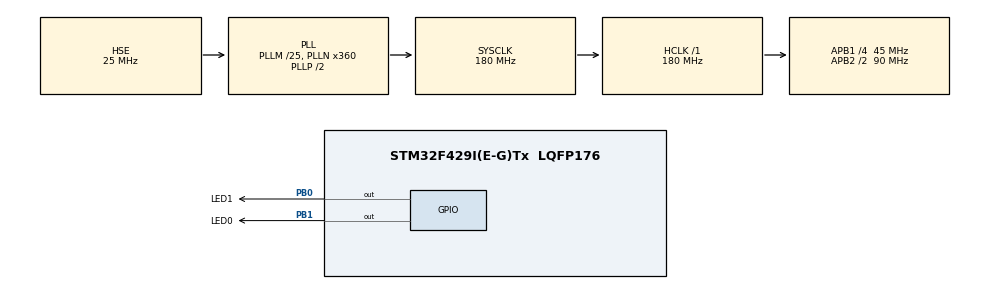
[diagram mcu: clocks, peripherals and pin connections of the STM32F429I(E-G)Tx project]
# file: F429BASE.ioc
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FREERTOS.Tasks01=defaultTask,24,128,StartDefaultTask,Default,NULL,Dynamic,NULL,NULL;myTask_LED0,8,128,StartTask_LED0,Default,NULL,Dynamic,NULL,NULL;myTask_LED1,8,128,StartTask_LED1,Default,NULL,Dynamic,NULL,NULL
Mcu.Family=STM32F4
Mcu.Name=STM32F429I(E-G)Tx
Mcu.Package=LQFP176
NVIC.PriorityGroup=NVIC_PRIORITYGROUP_4
NVIC.TIM6_DAC_IRQn=true\:15\:0\:false\:false\:true\:false\:false\:true\:true
NVIC.TimeBase=TIM6_DAC_IRQn
NVIC.TimeBaseIP=TIM6
PA13.Mode=Serial_Wire
PA13.Signal=SYS_JTMS-SWDIO
PA14.Mode=Serial_Wire
PA14.Signal=SYS_JTCK-SWCLK
PB0.GPIO_Label=LED1
PB0.Signal=GPIO_Output
PB1.GPIO_Label=LED0
PB1.Signal=GPIO_Output
PC14/OSC32_IN.Mode=LSE-External-Oscillator
PC14/OSC32_IN.Signal=RCC_OSC32_IN
PC15/OSC32_OUT.Mode=LSE-External-Oscillator
PC15/OSC32_OUT.Signal=RCC_OSC32_OUT
PH0/OSC_IN.Mode=HSE-External-Oscillator
PH0/OSC_IN.Signal=RCC_OSC_IN
PH1/OSC_OUT.Mode=HSE-External-Oscillator
PH1/OSC_OUT.Signal=RCC_OSC_OUT
ProjectManager.HeapSize=0x200
ProjectManager.StackSize=0x400
ProjectManager.TargetToolchain=CMake
RCC.48MHZClocksFreq_Value=90000000
RCC.AHBFreq_Value=180000000
RCC.APB1CLKDivider=RCC_HCLK_DIV4
RCC.APB1Freq_Value=45000000
RCC.APB1TimFreq_Value=90000000
RCC.APB2CLKDivider=RCC_HCLK_DIV2
RCC.APB2Freq_Value=90000000
RCC.APB2TimFreq_Value=180000000
RCC.CortexFreq_Value=180000000
RCC.HCLKFreq_Value=180000000
RCC.HSE_VALUE=25000000
RCC.HSI_VALUE=16000000
RCC.PLLM=25
RCC.PLLN=360
RCC.PLLSAIN=100
RCC.PLLSourceVirtual=RCC_PLLSOURCE_HSE
RCC.SYSCLKFreq_VALUE=180000000
RCC.SYSCLKSource=RCC_SYSCLKSOURCE_PLLCLK
RCC.VCOOutputFreq_Value=360000000
VP_FREERTOS_VS_CMSIS_V2.Mode=CMSIS_V2
VP_SYS_VS_tim6.Mode=TIM6
board=custom

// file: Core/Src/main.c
/* USER CODE BEGIN Header */
/**
  ******************************************************************************
  * @file           : main.c
  * @brief          : Main program body
  ******************************************************************************
  * @attention
  *
  * Copyright (c) 2026 STMicroelectronics.
  * All rights reserved.
  *
  * This software is licensed under terms that can be found in the LICENSE file
  * in the root directory of this software component.
  * If no LICENSE file comes with this software, it is provided AS-IS.
  *
  ******************************************************************************
  */
/* USER CODE END Header */
#include "main.h"
#include "cmsis_os.h"
#include "gpio.h"

void SystemClock_Config(void);
void MX_FREERTOS_Init(void);

int main(void)
{

  /* MCU Configuration--------------------------------------------------------*/

  /* Reset of all peripherals, Initializes the Flash interface and the Systick. */
  HAL_Init();

  /* Configure the system clock */
  SystemClock_Config();

  /* Initialize all configured peripherals */
  MX_GPIO_Init();

  /* Init scheduler */
  osKernelInitialize();  /* Call init function for freertos objects (in cmsis_os2.c) */
  MX_FREERTOS_Init();

  /* Start scheduler */
  osKernelStart();

  /* We should never get here as control is now taken by the scheduler */

  /* Infinite loop */
  while (1)
  {

    /* USER CODE BEGIN 3 */
      HAL_GPIO_TogglePin(LED0_GPIO_Port,LED0_Pin);
      //HAL_GPIO_TogglePin(LED1_GPIO_Port,LED1_Pin);
      HAL_Delay(500);
  }
  /* USER CODE END 3 */
}

void SystemClock_Config(void)
{
  RCC_OscInitTypeDef RCC_OscInitStruct = {0};
  RCC_ClkInitTypeDef RCC_ClkInitStruct = {0};

  /** Configure the main internal regulator output voltage
  */
  __HAL_RCC_PWR_CLK_ENABLE();
  __HAL_PWR_VOLTAGESCALING_CONFIG(PWR_REGULATOR_VOLTAGE_SCALE1);

  /** Initializes the RCC Oscillators according to the specified parameters
  * in the RCC_OscInitTypeDef structure.
  */
  RCC_OscInitStruct.OscillatorType = RCC_OSCILLATORTYPE_HSE;
  RCC_OscInitStruct.HSEState = RCC_HSE_ON;
  RCC_OscInitStruct.PLL.PLLState = RCC_PLL_ON;
  RCC_OscInitStruct.PLL.PLLSource = RCC_PLLSOURCE_HSE;
  RCC_OscInitStruct.PLL.PLLM = 25;
  RCC_OscInitStruct.PLL.PLLN = 360;
  RCC_OscInitStruct.PLL.PLLP = RCC_PLLP_DIV2;
  RCC_OscInitStruct.PLL.PLLQ = 4;
  if (HAL_RCC_OscConfig(&RCC_OscInitStruct) != HAL_OK)
  {
    Error_Handler();
  }

  /** Activate the Over-Drive mode
  */
  if (HAL_PWREx_EnableOverDrive() != HAL_OK)
  {
    Error_Handler();
  }

  /** Initializes the CPU, AHB and APB buses clocks
  */
  RCC_ClkInitStruct.ClockType = RCC_CLOCKTYPE_HCLK|RCC_CLOCKTYPE_SYSCLK
                              |RCC_CLOCKTYPE_PCLK1|RCC_CLOCKTYPE_PCLK2;
  RCC_ClkInitStruct.SYSCLKSource = RCC_SYSCLKSOURCE_PLLCLK;
  RCC_ClkInitStruct.AHBCLKDivider = RCC_SYSCLK_DIV1;
  RCC_ClkInitStruct.APB1CLKDivider = RCC_HCLK_DIV4;
  RCC_ClkInitStruct.APB2CLKDivider = RCC_HCLK_DIV2;

  if (HAL_RCC_ClockConfig(&RCC_ClkInitStruct, FLASH_LATENCY_5) != HAL_OK)
  {
    Error_Handler();
  }
}

void HAL_TIM_PeriodElapsedCallback(TIM_HandleTypeDef *htim)
{
  if (htim->Instance == TIM6)
  {
    HAL_IncTick();
  }
}

void Error_Handler(void)
{
  __disable_irq();
  while (1)
  {
  }
}

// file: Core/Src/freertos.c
/* USER CODE BEGIN Header */
/**
  ******************************************************************************
  * File Name          : freertos.c
  * Description        : Code for freertos applications
  ******************************************************************************
  * @attention
  *
  * Copyright (c) 2026 STMicroelectronics.
  * All rights reserved.
  *
  * This software is licensed under terms that can be found in the LICENSE file
  * in the root directory of this software component.
  * If no LICENSE file comes with this software, it is provided AS-IS.
  *
  ******************************************************************************
  */
/* USER CODE END Header */

#include "FreeRTOS.h"
#include "task.h"
#include "main.h"
#include "cmsis_os.h"

/* Definitions for defaultTask */
osThreadId_t defaultTaskHandle;
const osThreadAttr_t defaultTask_attributes = {
  .name = "defaultTask",
  .stack_size = 128 * 4,
  .priority = (osPriority_t) osPriorityNormal,
};
/* Definitions for myTask_LED0 */
osThreadId_t myTask_LED0Handle;
const osThreadAttr_t myTask_LED0_attributes = {
  .name = "myTask_LED0",
  .stack_size = 128 * 4,
  .priority = (osPriority_t) osPriorityLow,
};
/* Definitions for myTask_LED1 */
osThreadId_t myTask_LED1Handle;
const osThreadAttr_t myTask_LED1_attributes = {
  .name = "myTask_LED1",
  .stack_size = 128 * 4,
  .priority = (osPriority_t) osPriorityLow,
};

void StartDefaultTask(void *argument);
void StartTask_LED0(void *argument);
void StartTask_LED1(void *argument);

void MX_FREERTOS_Init(void); /* (MISRA C 2004 rule 8.1) */

void MX_FREERTOS_Init(void) {

  /* Create the thread(s) */
  /* creation of defaultTask */
  defaultTaskHandle = osThreadNew(StartDefaultTask, NULL, &defaultTask_attributes);

  /* creation of myTask_LED0 */
  myTask_LED0Handle = osThreadNew(StartTask_LED0, NULL, &myTask_LED0_attributes);

  /* creation of myTask_LED1 */
  myTask_LED1Handle = osThreadNew(StartTask_LED1, NULL, &myTask_LED1_attributes);

}

void StartDefaultTask(void *argument)
{
  for(;;)
  {
    osDelay(1);
  }
}

void StartTask_LED0(void *argument)
{
  /* USER CODE BEGIN StartTask_LED0 */
  /* Infinite loop */
  for(;;)
  {
      HAL_GPIO_TogglePin(LED0_GPIO_Port,LED0_Pin);
    osDelay(1000);
  }
  /* USER CODE END StartTask_LED0 */
}

void StartTask_LED1(void *argument)
{
  /* USER CODE BEGIN StartTask_LED1 */
  /* Infinite loop */
  for(;;)
  {
      HAL_GPIO_TogglePin(LED1_GPIO_Port,LED1_Pin);
    osDelay(750);
  }
  /* USER CODE END StartTask_LED1 */
}
